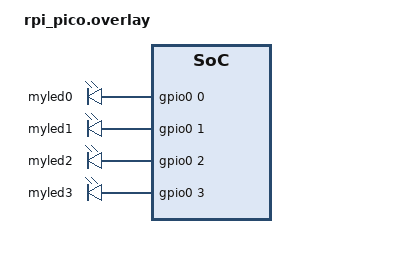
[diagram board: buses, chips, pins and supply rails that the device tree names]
/ {
     aliases {
             led0 = &myled0;
			 led1 = &myled1;
			 led2 = &myled2;
			 led3 = &myled3;
     };

     leds {
             compatible = "gpio-leds";
             myled0: led_0 {
                     gpios = <&gpio0 0 GPIO_ACTIVE_HIGH>;
             };
			 myled1: led_1 {
					 gpios = <&gpio0 1 GPIO_ACTIVE_HIGH>;
			 };
			 myled2: led_2 {
					 gpios = <&gpio0 2 GPIO_ACTIVE_HIGH>;
			 };
			 myled3: led_3 {
					 gpios = <&gpio0 3 GPIO_ACTIVE_HIGH>;
			 };
			 
			 
     };
};
